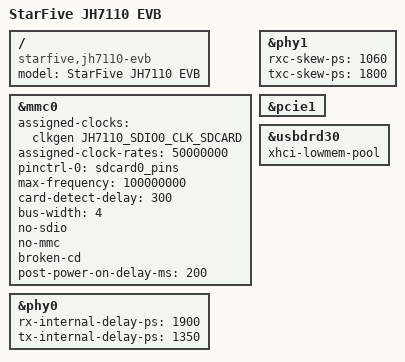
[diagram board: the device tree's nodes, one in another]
// SPDX-License-Identifier: GPL-2.0 OR MIT
/*
 * Copyright (C) 2022 StarFive Technology Co., Ltd.
 * Copyright (C) 2022 Hal Feng <hal.feng@starfivetech.com>
 */

/dts-v1/;
#include "jh7110-evb.dtsi"

/ {
	model = "StarFive JH7110 EVB";
	compatible = "starfive,jh7110-evb", "starfive,jh7110";
};

/* default sd card */
&mmc0 {
	assigned-clocks = <&clkgen JH7110_SDIO0_CLK_SDCARD>;
	assigned-clock-rates = <50000000>;
	pinctrl-names = "default";
	pinctrl-0 = <&sdcard0_pins>;
	max-frequency = <100000000>;
	card-detect-delay = <300>;
	bus-width = <4>;
	no-sdio;
	no-mmc;
	broken-cd;
	post-power-on-delay-ms = <200>;
	status = "okay";
};

&phy0 {
	rx-internal-delay-ps = <1900>;
	tx-internal-delay-ps = <1350>;
};

&phy1 {
	rxc-skew-ps = <1060>;
	txc-skew-ps = <1800>;
};

&pcie1 {
	status = "okay";
};

&usbdrd30 {
	xhci-lowmem-pool;
	status = "okay";
};
